# tviic2d6m register map
Vendor: Infineon Technologies; Series: TVIIC2D6M; File version: 1.0
CPU: CM7 r0p1, little endian, MPU, FPU, double-precision FPU, I-cache, D-cache, VTOR, ITCM, DTCM, 3 interrupt priority bits, 16 interrupts
Registers are 32-bit, read-write, reset 0x0 unless marked. A register's access mark holds for its fields unless they carry their own. Offsets are from the block's base; [hi:lo] are bit positions; lines under a group give offsets from that group; {n}, {i} and the like mark numbered series.

## DMAC
Base 0x402A0000
0x00 CTL — Control
  [31] ENABLED — IP enable: '0': Disabled. All non-retention registers (command and status registers) are reset to their default value when the IP is disabled. All retention registers retain their value when the IP is disabled. '1': Enabled.
    0=DISABLED (N/A); 1=ENABLED (N/A)
0x08 ACTIVE ro — Active channels
  [7:0] ACTIVE — Specifies active channels; i.e. enabled channels whose trigger got activated.
{0x1000+0x100*i} CH[{i}] (i=0..7) group — DMA controller channel
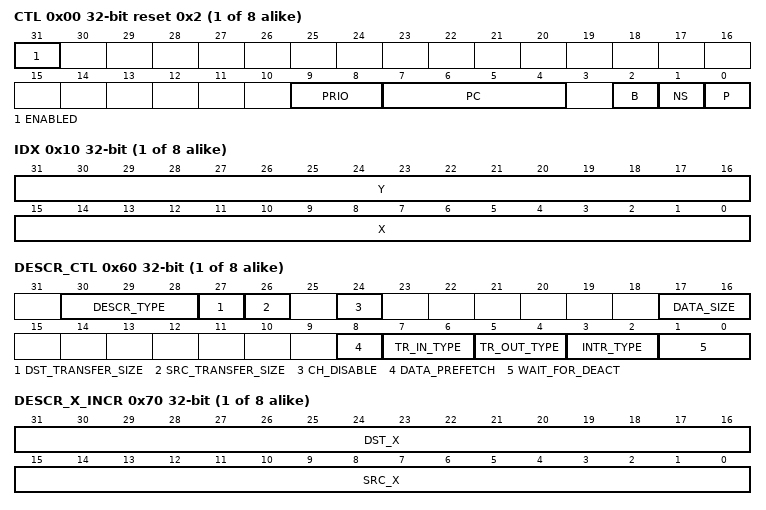
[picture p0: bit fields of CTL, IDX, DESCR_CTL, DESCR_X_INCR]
  0x00 CTL reset 0x2 — Channel control
    [31] ENABLED — Channel enable: '0': Disabled. The channel's trigger is ignored and the channel cannot be made pending and therefore cannot be made active. If a pending channel is disabled, the channel is made non pending. If the activate channel is disabled, the channel is de-activated (bus transactions are completed). '1': Enabled. SW sets this field to '1' to enable a specific channel. HW sets this field to '0' when an error interrupt cause is activated.
    [9:8] PRIO — Channel priority: '0': highest priority. '1' '2' '3': lowest priority. Channels with the same priority constitute a priority group and within this priority group, the following 'roundrobin' arbitration is applied. A 'round' consists of a contiguous sequence of channel activations, within this priority group, without any repetition. Within a round, higher priority is given to the lower channel indices. The notion of a round guarantees that within a group, higher channel indices do not yield to lower indices indefinitely.
    [7:4] PC — Protection context. This field is set with the protection context of the transaction that writes this register; i.e. the context is inherited from the write transaction and not specified by the transaction write data. All transactions for this channel uses the PC field for the protection context.
    [2] B — Non-bufferable/bufferable access control: '0': non-bufferable. '1': bufferable. This field is used to indicate to an AMBA bridge that a write transaction can complete without waiting for the destination to accept the write transaction data. All transactions for this channel uses the B field for the non-bufferable/bufferable access control ('hprot[2]').
    [1] NS — Secure/on-secure access control: '0': secure. '1': non-secure. This field is set with the secure/non-secure access control of the transaction that writes this register; i.e. the access control is inherited from the write transaction and not specified by the transaction write data. All transactions for this channel use the NS field for the secure/non-secure access control ('hprot[4]').
    [0] P — User/privileged access control: '0': user mode. '1': privileged mode. This field is set with the user/privileged access control of the transaction that writes this register; i.e. the access control is inherited from the write transaction and not specified by the transaction write data. All transactions for this channel use the P field for the user/privileged access control ('hprot[1]').
  0x10 IDX ro reset not defined — Channel current indices
    [31:16] Y — Specifies the Y loop index, with Y_COUNT taken from the current descriptor. Note: HW sets this field to '0' when it loads a descriptor..
    [15:0] X — Specifies the X loop index. In the range of [0, X_COUNT], with X_COUNT taken from the current descriptor. Note: HW sets this field to '0' when it loads a descriptor.
  0x14 SRC ro reset not defined — Channel current source address
    [31:0] ADDR — Current address of source location.
  0x18 DST ro reset not defined — Channel current destination address
    [31:0] ADDR — Current address of destination location.
  0x20 CURR reset not defined — Channel current descriptor pointer
    [31:2] PTR — Address of current descriptor. When this field is '0', there is no valid descriptor. Note: HW updates the current descriptor pointer CH_CURR_PTR with DESCR_NEXT_PTR after execution of the current descriptor.
  0x28 TR_CMD — Channle software trigger
    [0] ACTIVATE write-1-sets — Software trigger. When written with '1', a trigger is generated which sets 'trigger pending' (only if the channel is enabled). A read always returns a 0.
  0x40 DESCR_STATUS ro — Channel descriptor status
    [31] VALID — Indicates whether the descriptor information present in DESCR_CTL, DESCR_SRC, DESCR_DST, DESCR_X_SIZE, DESCR_X_INCR, DESCR_Y_SIZE, DESCR_Y_INCR, DESCR_NEXT status registers is valid or not.
  0x60 DESCR_CTL ro reset not defined — Channel descriptor control
    [30:28] DESCR_TYPE — Specifies the descriptor type (not to be confused with the trigger type): '0': Single transfer. The DESCR_X_SIZE, DESCR_X_INCR, DESCR_Y_SIZE and DESCR_Y_INCR registers are NOT present. The DESCR_NEXT_PTR is at offset 0x0c. '1': 1D transfer. The DESCR_X_SIZE and DESCR_X_INCR registers are present, the DESCR_Y_SIZE and DESCR_Y_INCR are NOT present. A 1D transfer consists out of DESCR_X_SIZE.X_COUNT+1 single transfers. The DESCR_NEXT_PTR is at offset 0x14. '2': 2D transfer. The DESCR_X_SIZE, DESCR_X_INCR, DESCR_Y_SIZE and DESCR_Y_INCR registers are present. A 2D transfer consists of (DESCR_X_SIZE.X_COUNT+1)*(DESCR_Y_SIZE.Y_COUNT+1) single transfers. The DESCR_NEXT_PTR is at offset 0x1c. '3': Memory copy. The DESCR_X_SIZE register is present, the DESCR_X_INCR, DESCR_Y_SIZE and DESCR_Y_INCR are NOT present. A memory copy transfer copies DESCR_X_SIZE.X_COUNT+1 Bytes and may use Byte, halfword and word transfers. The DESCR_NEXT_PTR is at offset 0x10. '4': Scatter transfer. The DESCR_X_SIZE register is present, the DESCR_DST, DESCR_X_INCR, DESCR_Y_SIZE and DESCR_Y_INCR are NOT present. '5'-'7': Undefined. After the execution of the current descriptor, the DESCR_NEXT_PTR address is copied to the channel's CH_CURR_PTR address and CH_STATUS.X_IDX and CH_STATUS.Y_IDX are set to '0'.
    [27] DST_TRANSFER_SIZE — Specifies the bus transfer size to the destination location: '0': As specified by DATA_SIZE. '1': Word (32 bits). Distinguishing bus transfer size from data element size allows for destination components with data elements that are smaller than their 32-bit bus interface width. E.g., a DAC destination has a 32-bit bus transfer size, but only requires a 16-bit data element. Note: this field is not used for a 'memory copy' descriptor type. Note: this field must be set to '1' for a 'scatter' descriptor type.
    [26] SRC_TRANSFER_SIZE — Specifies the bus transfer size to the source location: '0': As specified by DATA_SIZE. '1': Word (32 bits). Distinguishing bus transfer size from data element size allows for source components with data elements that are smaller than their 32-bit bus interface width. E.g., an ADC source has a 32-bit bus transfer size, but only provides a 16-bit data element. Note: this field is not used for a 'memory copy' descriptor type. Note: this field must be set to '1' for a 'scatter' descriptor type.
    [24] CH_DISABLE — Specifies whether the channel is disabled or not after completion of the current descriptor (independent of the value of the DESCR_NEXT_PTR value): '0': Channel is not disabled. '1': Channel is disabled.
    [17:16] DATA_SIZE — Specifies the data element size: '0': Byte (8 bits). '1': Halfword (16 bits). '2': Word (32 bits). DATA_SIZE, SRC_TRANSFER_SIZE and DST_TRANSFER_SIZE together determine how data elements are transferred. The following are the 9 legal settings: - DATA is 8 bit, SRC is 8 bit, DST is 8 bit. - DATA is 8 bit, SRC is 32 bit (higher 24 bits are dropped), DST is 8 bit. - DATA is 8 bit, SRC is 8 bit, DST is 32 bit (higher 24 bits are made '0'). - DATA is 8 bit, SRC is 32 bit (higher 24 bits are dropped), DST is 32 bit (higher 24 bits are made '0'). - DATA is 16 bit, SRC is 16 bit, DST is 16 bit. - DATA is 16 bit, SRC is 32 bit (higher 16 bits are dropped), DST is 16 bit. - DATA is 16 bit, SRC is 16 bit, DST is 32 bit (higher 16 bits are made '0'). - DATA is 16 bit, SRC is 32 bit (higher 16 bits are dropped), DST is 32 bit (higher 16 bits are made '0'). - DATA is 32 bit, SRC is 32 bit, DST is 32 bit. Note: this field is not used for a 'memory copy' descriptor type. Note: this field must be set to '2' for a 'initialization' descriptor type.
    [8] DATA_PREFETCH — Source data prefetch: '0': No source data prefetch. Source data transfers are only initiated AFTER the input trigger is activated. '1': Source data prefetch. Source data transfers are initiated as soon as the channel is enabled, the current descriptor pointer is NOT '0' and there is space available in the channel's data FIFO. When the input trigger is activated, the trigger can initiate destination data transfers with data that is already in the channel's data FIFO. This effectively shortens the initial delay of the data transfer. Note: data prefetch should be used with care, to ensure that data coherency is guaranteed and that prefetches do not cause undesired side effects.
    [7:6] TR_IN_TYPE — Specifies the input trigger type (not to be confused with the descriptor type): '0': A trigger results in the execution of a single transfer. The descriptor type can be single, 1D or 2D. '1': A trigger results in the execution of a single 1D transfer. - If the descriptor type is 'single', the trigger results in the execution of a single transfer. - If the descriptor type is '1D' or '2D', the trigger results in the execution of a 1D transfer. - If the descriptor type is 'memory copy', the trigger results in the execution of a memory copy transfer. - If the descriptor type is 'scatter', the trigger results in the execution of an scatter transfer. '2': A trigger results in the execution of the current descriptor. '3': A trigger results in the execution of the current descriptor and continues (without requiring another input trigger) with the execution of the next descriptor using the next descriptor's information.
    [5:4] TR_OUT_TYPE — Specifies when an output trigger is generated: '0': An output trigger is generated after a single transfer. '1': An output trigger is generated after a single 1D transfer or a memory copy transfer. - If the descriptor type is 'single', the output trigger is generated after a single transfer. - If the descriptor type is '1D' or '2D', the output trigger is generated after the execution of a 1D transfer. - If the descriptor type is 'memory copy', the output trigger is generated after the execution of a memory copy transfer. - If the descriptor type is 'scatter', the output trigger is generated after the execution of a scatter transfer. '2': An output trigger is generated after the execution of the current descriptor. '3': An output trigger is generated after the execution of a descriptor list: after the execution of the current descriptor AND the current descriptor's DESCR_NEXT_PTR.ADDR is '0'.
    [3:2] INTR_TYPE — Specifies when a completion interrupt is generated (CH_STATUS.INTR_CAUSE is set to COMPLETION): '0': An interrupt is generated after a single transfer. '1': An interrupt is generated after a single 1D transfer or a memory copy transfer - If the descriptor type is 'single', the interrupt is generated after a single transfer. - If the descriptor type is '1D' or '2D', the interrupt is generated after the execution of a 1D transfer. - If the descriptor type is 'memory copy', the interrupt is generated after the execution of a memory copy transfer. - If the descriptor type is 'scatter' the interrupt is generated after the execution of a scatter transfer. '2': An interrupt is generated after the execution of the current descriptor (independent of the value of DESCR_NEXT_PTR.ADDR of the current descriptor). '3': An interrupt is generated after the execution of the current descriptor and the current descriptor's DESCR_NEXT_PTR.ADDR is '0'.
    [1:0] WAIT_FOR_DEACT — Specifies whether the controller should wait for the input trigger to be deactivated; i.e. the selected system trigger is not active. This field is used to synchronize the controller with the agent that generated the trigger. This field is ONLY used at the completion of the transfer as specified by TR_IN. E.g., a TX FIFO indicates that it is empty and it needs a new data sample. The agent removes the trigger ONLY when the data sample has been written by the controller AND received by the agent. Furthermore, the agent's trigger may be delayed by a few cycles before it reaches the controller. This field is used for level sensitive trigger, which reflect state (pulse sensitive triggers should have this field set to '0'). The wait cycles incurred by this field reduce DW controller performance. '0': Do not wait for trigger de-activation (for pulse sensitive triggers). '1': Wait for up to 4 cycles. '2': Wait for up to 16 cycles. '3': Wait indefinitely. This option may result in controller lockup if the trigger is not de-activated.
  0x64 DESCR_SRC ro reset not defined — Channel descriptor source
    [31:0] ADDR — Base address of source location.
  0x68 DESCR_DST ro reset not defined — Channel descriptor destination
    [31:0] ADDR — Base address of destination location.
  0x6C DESCR_X_SIZE ro reset not defined — Channel descriptor X size
    [15:0] X_COUNT — Number of iterations (minus 1) of the 'X loop' (X_COUNT+1 is the number of single transfers in a 1D transfer). This field is an unsigned number in the range [0, 65535], representing 1 through 65536 iterations. For the 'memory copy' descriptor type, (X_COUNT + 1) is the number of transferred Bytes. For the 'scatter' descriptor type, ceiling(X_COUNT/2) is the number of (address, write data) initialization pairs processed.
  0x70 DESCR_X_INCR ro reset not defined — Channel descriptor X increment
    [31:16] DST_X — Specifies increment of destination address for each X loop iteration (in multiples of DST_TRANSFER_SIZE). This field is a signed number (sign-magnitude format) in the range [-32768, 32767]. If this field is '0', the destination address is not incremented. This is useful for writing to TX FIFO structures.
    [15:0] SRC_X — Specifies increment of source address for each X loop iteration (in multiples of SRC_TRANSFER_SIZE). This field is a signed number (sign-magnitude format) in the range [-32768, 32767]. If this field is '0', the source address is not incremented. This is useful for reading from RX FIFO structures.
  0x74 DESCR_Y_SIZE ro reset not defined — Channel descriptor Y size
    [15:0] Y_COUNT — Number of iterations (minus 1) of the 'Y loop' (X_COUNT+1)*(Y_COUNT+1) is the number of single transfers in a 2D transfer). This field is an unsigned number in the range [0, 65535], representing 1 through 65536 iterations.
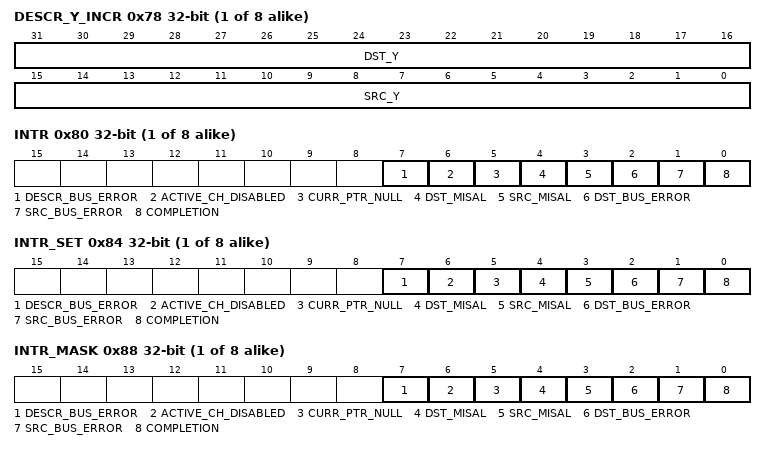
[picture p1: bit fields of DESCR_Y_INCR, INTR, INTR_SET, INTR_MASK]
  0x78 DESCR_Y_INCR ro reset not defined — Channel descriptor Y increment
    [31:16] DST_Y — Specifies increment of destination address for each Y loop iteration (in multiples of DST_TRANSFER_SIZE). This field is a signed number in the range [-32768, 32767].
    [15:0] SRC_Y — Specifies increment of source address for each Y loop iteration (in multiples of SRC_TRANSFER_SIZE). This field is a signed number in the range [-32768, 32767].
  0x7C DESCR_NEXT ro reset not defined — Channel descriptor next pointer
    [31:2] PTR — Address of next descriptor in descriptor list. When this field is '0', this is the last descriptor in the descriptor list.
  0x80 INTR — Interrupt
    [7] DESCR_BUS_ERROR write-1-clears — Activated (set to '1') on a bus error for a load of the descriptor.
    [6] ACTIVE_CH_DISABLED write-1-clears — Activated (set to '1') if the channel is disabled by SW (accidentally/incorrectly) when the data transfer engine is busy.
    [5] CURR_PTR_NULL write-1-clears — Activated (set to '1') when the channel is enabled (CH_CTL.ENABLED is '1') and CH_CURR_PTR is '0'.
    [4] DST_MISAL write-1-clears — Activated (set to '1') on a misalignment of the destination address.
    [3] SRC_MISAL write-1-clears — Activated (set to '1') on a misalignment of the source address.
    [2] DST_BUS_ERROR write-1-clears — Activated (set to '1') on a bus error for a store to the destination.
    [1] SRC_BUS_ERROR write-1-clears — Activated (set to '1') on a bus error for a load from the source.
    [0] COMPLETION write-1-clears — Activated (set to '1') on completion of data transfer(s) as specified by the descriptor's CH_DESCR_CTL.INTR_TYPE.
  0x84 INTR_SET — Interrupt set
    [7] DESCR_BUS_ERROR write-1-sets — Write this field with '1' to set INTR.DESCR_BUS_ERROR field to '1' (a write of '0' has no effect).
    [6] ACTIVE_CH_DISABLED write-1-sets — Write this field with '1' to set INTR.ACT_CH_DISABLED field to '1' (a write of '0' has no effect).
    [5] CURR_PTR_NULL write-1-sets — Write this field with '1' to set INTR.CURR_PTR_NULL field to '1' (a write of '0' has no effect).
    [4] DST_MISAL write-1-sets — Write this field with '1' to set INTR.DST_MISAL field to '1' (a write of '0' has no effect).
    [3] SRC_MISAL write-1-sets — Write this field with '1' to set INTR.SRC_MISAL field to '1' (a write of '0' has no effect).
    [2] DST_BUS_ERROR write-1-sets — Write this field with '1' to set INTR.DST_BUS_ERROR field to '1' (a write of '0' has no effect).
    [1] SRC_BUS_ERROR write-1-sets — Write this field with '1' to set INTR.SRC_BUS_ERROR field to '1' (a write of '0' has no effect).
    [0] COMPLETION write-1-sets — Write this field with '1' to set INTR.COMPLETION field to '1' (a write of '0' has no effect).
  0x88 INTR_MASK — Interrupt mask
    [7] DESCR_BUS_ERROR — Mask for INTR.DESCR_BUS_ERROR interrupt.
    [6] ACTIVE_CH_DISABLED — Mask for INTR.ACTIVE_CH_DISABLED interrupt.
    [5] CURR_PTR_NULL — Mask for INTR.CURR_PTR_NULL interrupt.
    [4] DST_MISAL — Mask for INTR.DST_MISAL interrupt.
    [3] SRC_MISAL — Mask for INTR.SRC_MISAL interrupt.
    [2] DST_BUS_ERROR — Mask for INTR.DST_BUS_ERROR interrupt.
    [1] SRC_BUS_ERROR — Mask for INTR.SRC_BUS_ERROR interrupt.
    [0] COMPLETION — Mask for INTR.COMPLETION interrupt.
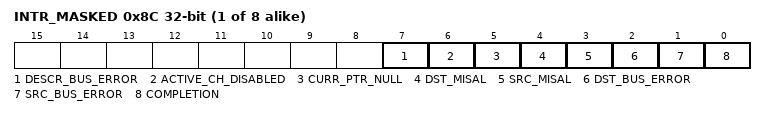
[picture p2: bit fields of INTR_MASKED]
  0x8C INTR_MASKED ro — Interrupt masked
    [7] DESCR_BUS_ERROR — Logical and of corresponding INTR.DESCR_BUS_ERROR and INTR_MASK.DESCR_BUS_ERROR fields.
    [6] ACTIVE_CH_DISABLED — Logical and of corresponding INTR.ACTIVE_CH_DISABLED and INTR_MASK.ACTIVE_CH_DISABLED fields.
    [5] CURR_PTR_NULL — Logical and of corresponding INTR.CURR_PTR_NULL and INTR_MASK.CURR_PTR_NULL fields.
    [4] DST_MISAL — Logical and of corresponding INTR.DST_MISAL and INTR_MASK.DST_MISAL fields.
    [3] SRC_MISAL — Logical and of corresponding INTR.SRC_MISAL and INTR_MASK.SRC_MISAL fields.
    [2] DST_BUS_ERROR — Logical and of corresponding INTR.DST_BUS_ERROR and INTR_MASK.DST_BUS_ERROR fields.
    [1] SRC_BUS_ERROR — Logical and of corresponding INTR.SRC_BUS_ERROR and INTR_MASK.SRC_BUS_ERROR fields.
    [0] COMPLETION — Logical and of corresponding INTR.COMPLETION and INTR_MASK.COMPLETION fields.
